# LPC2103 register map
Series: LPC2000; File version: r4p0
CPU: other r0p0, selectable endian, no FPU, vendor SysTick, 2 interrupt priority bits
Registers are read-write, reset 0x0 unless marked. A register's access mark holds for its fields unless they carry their own. Offsets are from the block's base; [hi:lo] are bit positions; lines under a group give offsets from that group; {n}, {i} and the like mark numbered series; 'fields as' and 'values as' point back to an identical list.

## SPI — Serial Peripheral Interface
Base 0xE0020000
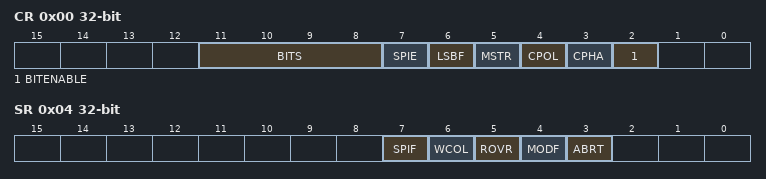
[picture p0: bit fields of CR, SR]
0x00 CR — Control Register
  [11:8] BITS
    {v}={v}BIT (v=8..15); 0=16BIT
  [7] SPIE
  [6] LSBF
  [5] MSTR
  [4] CPOL
  [3] CPHA
  [2] BITENABLE
0x04 SR ro — Status Register
  [7] SPIF, [6] WCOL, [5] ROVR, [4] MODF, [3] ABRT
0x08 DR — Data Register
  [15:0] DATA
0x0C CCR — Clock Counter Register
  [7:0] COUNTER
0x1C INT write-1-clears — Interrupt Register
  [0] SPIIF

## SSP — Synchronous Serial Port
Base 0xE0068000
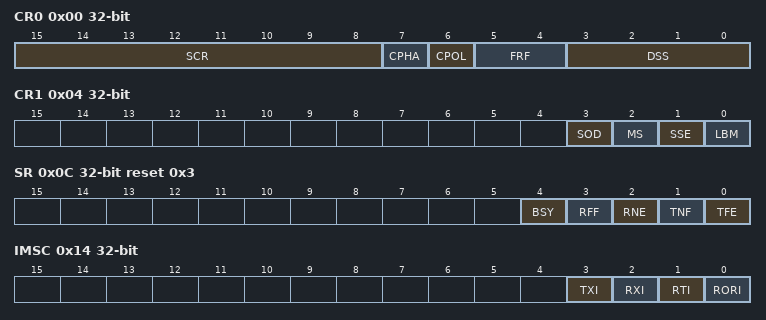
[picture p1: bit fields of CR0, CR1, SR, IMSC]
0x00 CR0 — Control Register 0
  [15:8] SCR — Serial Clock Rate
  [7] CPHA
  [6] CPOL
  [5:4] FRF — Frame Format
    0=SPI; 1=SSI; 2=MICROWIRE
  [3:0] DSS range 3..15 — Data Size Select
0x04 CR1 — Configuration Register 1
  [3] SOD — Slave Output Disable
  [2] MS — Master/Slave Select
    0=MASTER; 1=SLAVE
  [1] SSE — SSP Enable
  [0] LBM — Loopback Mode
0x08 DR — Data Register
  [15:0] DATA
0x0C SR reset 0x3 — Status Register
  [4] BSY, [3] RFF, [2] RNE, [1] TNF, [0] TFE
0x10 CPSR — Clock Prescaler Register
  [7:1] CLKDIV range 1..127
0x14 IMSC — Interrupt Enable Register
  [3] TXI, [2] RXI, [1] RTI, [0] RORI
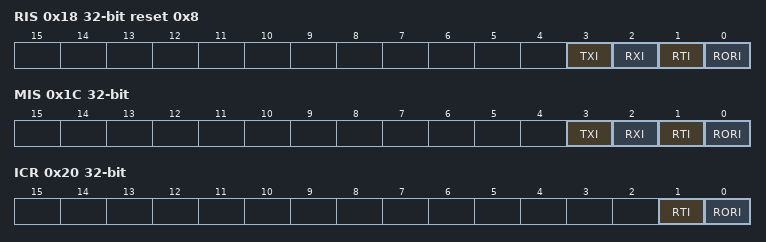
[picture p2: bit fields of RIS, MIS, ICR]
0x18 RIS ro reset 0x8 — Raw Interrupt Status Register
  [3] TXI, [2] RXI, [1] RTI, [0] RORI
0x1C MIS ro — Masked Interrupt Status Register
  [3] TXI, [2] RXI, [1] RTI, [0] RORI
0x20 ICR wo write-1-clears — Interrupt Clear Register
  [1] RTI, [0] RORI

## ADC — Analog-to-Digital Converter
Base 0xE0034000
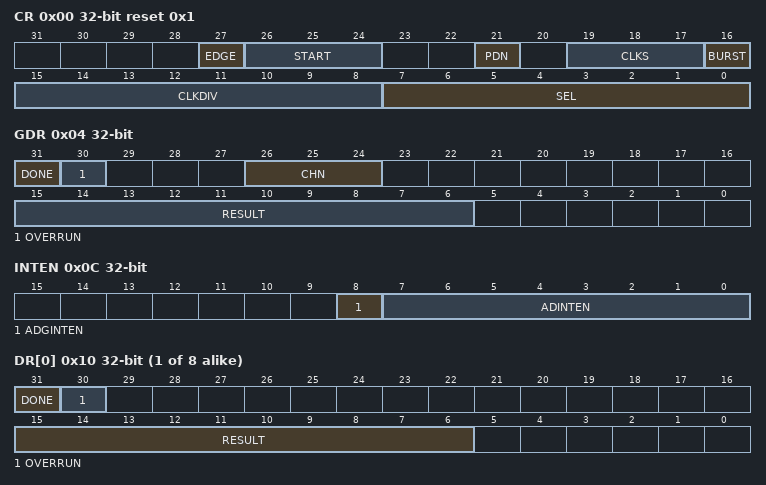
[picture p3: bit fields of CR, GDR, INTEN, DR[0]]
0x00 CR reset 0x1 — Control Register
  [27] EDGE
  [26:24] START — Trigger source for ADC conversion
    0=NONE; 1=NOW; 2=P0_16; 3=P0_22; 4=MAT0_1; 5=MAT0_3; 6=MAT1_0; 7=MAT1_1
  [21] PDN
  [19:17] CLKS
  [16] BURST
    0=ONESHOT; 1=CONTINUOUS
  [15:8] CLKDIV
  [7:0] SEL
0x04 GDR — Global Data Register
  [31] DONE, [30] OVERRUN, [26:24] CHN, [15:6] RESULT
0x0C INTEN — Interrupt Enable
  [8] ADGINTEN, [7:0] ADINTEN
{0x10+4i} DR[{i}] (i=0..7) ro — Data Register {i}
  [31] DONE, [30] OVERRUN, [15:6] RESULT
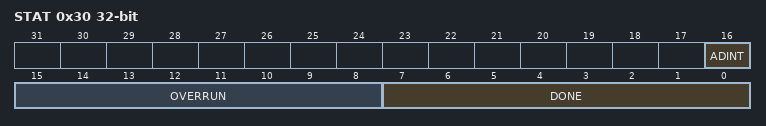
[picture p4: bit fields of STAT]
0x30 STAT ro — Status Register
  [16] ADINT, [15:8] OVERRUN, [7:0] DONE

## TIMER0 — General Purpose Timer 0
Base 0xE0004000
Same registers: TIMER1 0xE0008000, TIMER2 0xE0070000, TIMER3 0xE0074000
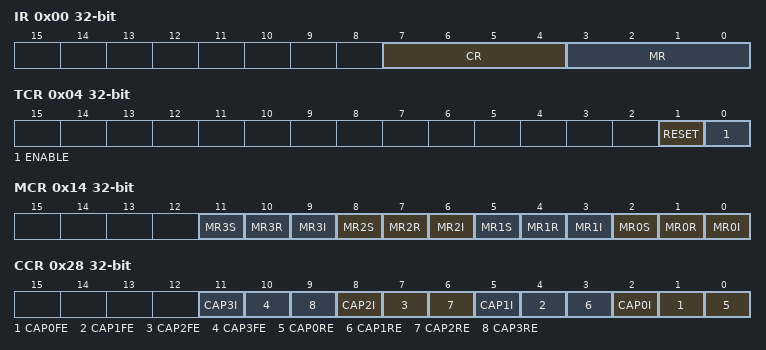
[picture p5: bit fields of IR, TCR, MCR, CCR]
0x00 IR — Interrupt Register
  [7:4] CR, [3:0] MR
0x04 TCR — Timer Control Register
  [1] RESET, [0] ENABLE
0x08 TC — Timer Counter
0x0C PR — Prescale Register
0x10 PC — Prescale Counter
0x14 MCR — Match Control Register
  [3n+2] MR{n}S (n=0..3), [3n+1] MR{n}R (n=0..3), [3n] MR{n}I (n=0..3)
{0x18+4i} MR[{i}] (i=0..3) — Match Register {i}
0x28 CCR — Capture Control Register
  [3n+2] CAP{n}I (n=0..3), [3n+1] CAP{n}FE (n=0..3), [3n] CAP{n}RE (n=0..3)
{0x2C+4i} CR[{i}] (i=0..3) ro — Capture Register {i}
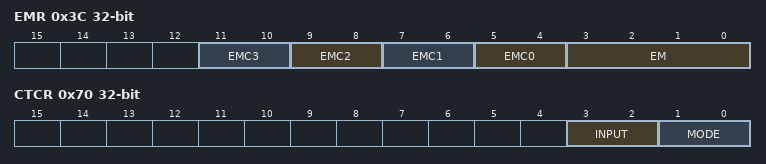
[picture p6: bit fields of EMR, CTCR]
0x3C EMR — External Match Register
  [2n+5:2n+4] EMC{n} (n=0..3)
    0=NONE; 1=CLEAR; 2=SET; 3=TOGGLE
  [3:0] EM
0x70 CTCR — Count Control Register
  [3:2] INPUT
  [1:0] MODE
    0=TIMER; 1=CAPRISE; 2=CAPFALL; 3=CAPBOTH
0x74 PWMCON — PWM Control Register
  [3:0] PWMEN

## WDT — Watchdog Timer
Base 0xE0000000
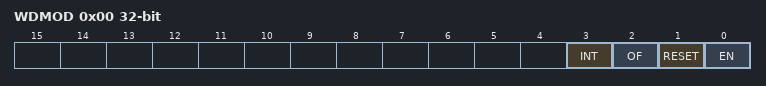
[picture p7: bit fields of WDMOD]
0x00 WDMOD — Watchdog Mode
  [3] INT ro — WDT Interrupt Fired
  [2] OF ro — WDT Overflowed
  [1] RESET write-1-sets — WDT causes RESET
  [0] EN write-1-sets — WDT Enabled
0x04 TC reset 0xFF — Timer Constant Register
0x08 FEED wo — Watchdog Fodder
  [7:0] FODDER
    170=KEY0; 85=KEY1
0x0C TV ro reset 0xFF — Timer Value Register

## RTC — Real-time Clock
Base 0xE0024000
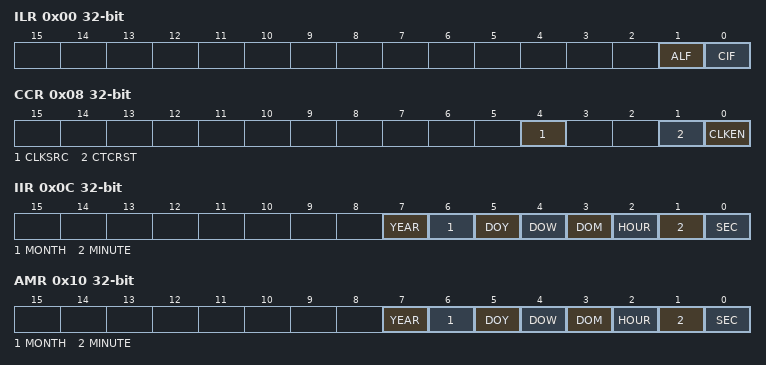
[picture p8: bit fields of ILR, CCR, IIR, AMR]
0x00 ILR write-1-clears — Interrupt Location Register
  [1] ALF, [0] CIF
0x04 CTC ro — Clock Tick Counter
  [15:1] TICKS
0x08 CCR — Clock Control Register
  [4] CLKSRC
    0=PREDIV; 1=RTCXT
  [1] CTCRST
  [0] CLKEN
0x0C IIR — Increment Interrupt Register
  [7] YEAR, [6] MONTH, [5] DOY, [4] DOW, [3] DOM, [2] HOUR, [1] MINUTE, [0] SEC
0x10 AMR — Alarm Mask Register
  fields as IIR
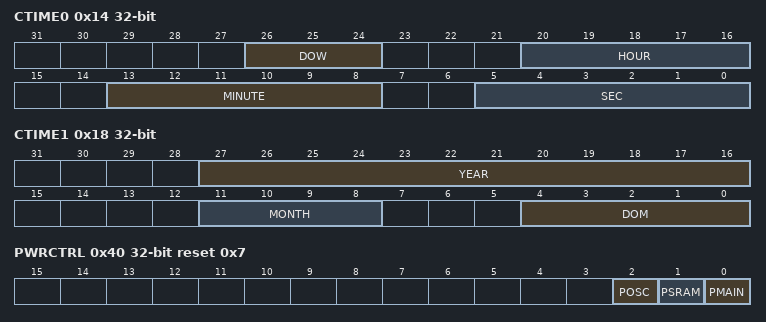
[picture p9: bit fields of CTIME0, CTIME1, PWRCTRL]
0x14 CTIME0 ro — Consolidated Time Register 0
  [26:24] DOW, [20:16] HOUR, [13:8] MINUTE, [5:0] SEC
0x18 CTIME1 ro — Consolidated Time Register 1
  [27:16] YEAR, [11:8] MONTH, [4:0] DOM
0x1C CTIME2 ro — Consolidated Time Register 2
  [11:0] DOY
0x20 NOW group — Datetime
  0x00 SEC range 0..59
  0x04 MINUTE range 0..59
  0x08 HOUR range 0..23
  0x0C DOM range 1..31 — Day of Month
  0x10 DOW range 0..6 — Day of Week
  0x14 DOY range 1..366 — Day of Year
  0x18 MONTH range 1..12
  0x1C YEAR range 0..4095
0x40 PWRCTRL reset 0x7 — Low Power Mode Control
  [2] POSC, [1] PSRAM, [0] PMAIN
{0x44+4i} GPREG[{i}] (i=0..2) — General Purpose Register
0x60 ALARM group — Alarm Datetime
  0x00 SEC range 0..59
  0x04 MINUTE range 0..59
  0x08 HOUR range 0..23
  0x0C DOM range 1..31 — Day of Month
  0x10 DOW range 0..6 — Day of Week
  0x14 DOY range 1..366 — Day of Year
  0x18 MONTH range 1..12
  0x1C YEAR range 0..4095
0x80 PREINT — RTC Prescaler Integer Part
  [12:0] PREINT
0x84 PREFRAC — RTC Prescaler Fraction Part
  [14:0] PREFRAC
